# AE302F80F55D5AE_CM55_HP_View register map
Vendor: Alif Semiconductor; Series: E3; File version: 1.0
CPU: CM55 r1p0, selectable endian, MPU, FPU, double-precision FPU, DSP, VTOR, 8 interrupt priority bits, 1 SAU regions
Registers are 32-bit, read-write, reset 0x0 unless marked. A register's access mark holds for its fields unless they carry their own. Offsets are from the block's base; [hi:lo] are bit positions; lines under a group give offsets from that group; {n}, {i} and the like mark numbered series.

## STOP_MODE
Base 0x1A60F000
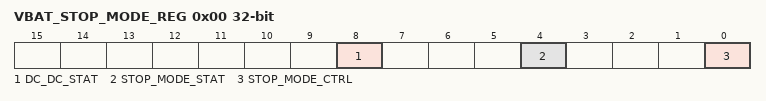
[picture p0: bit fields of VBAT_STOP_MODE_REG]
0x00 VBAT_STOP_MODE_REG — VBAT Stop Mode Control and Status Register
  [8] DC_DC_STAT ro — DC-DC Status Reflects the real-time status of DC-DC power
    0=DC-DC is ON; 1=DC-DC is OFF
  [4] STOP_MODE_STAT write-1-clears — Stop Mode Status - HW sets this bit when DC-DC was turned off - SW clears this bit by writing 0x1
  [0] STOP_MODE_CTRL — Stop Mode Control - SW sets this bit to enter stop mode - HW clears this bit when there is a wake-up event

## EVTRTR1
Base 0x400E2000
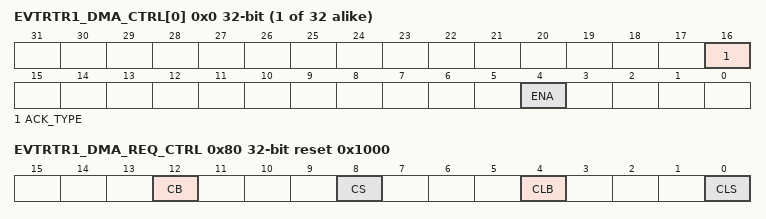
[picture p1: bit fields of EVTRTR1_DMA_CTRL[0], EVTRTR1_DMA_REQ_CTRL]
{0x0+4i} EVTRTR1_DMA_CTRL[{i}] (i=0..31) — DMA/Event Router Control and Status Register (n)
  [16] ACK_TYPE ro — DMA handshake type status for DMA peripheral
    0=Peripheral completes the REQ-ACK handshake with DMA controller. Event Router passing through REQ-ACK between DMA controller and peripheral.; 1=Event Router completes the REQ-ACK handshake with DMA controller. Peripheral raises DMA request without responding to ACK from DMA controller.
  [4] ENA — DMA channel enable
    0=Disable DMA channel; 1=Enable DMA channel
0x80 EVTRTR1_DMA_REQ_CTRL reset 0x1000 — DMA Request Control Register
  [all] fields
    0=Disable; 1=Enable
  [12] CB — Enable DMA request on DMACBREQ (DMAC Burst Request) Note: It is recommended to enable all DMA requests on the burst request line (DMACBREQ). For single transfer, the number of beats in a burst should be set to 1 (DMA_CCRn[SRC_BURST_LEN] = 0x0).
  [8] CS — Enable DMA request on DMACSREQ (DMAC Single Request) Note: It is recommended to enable all DMA requests on the burst request line (DMACBREQ), even for single transfer.
  [4] CLB — Enable DMA request on DMACLBREQ (DMAC Last Burst Request) Note: Do not use. The current implementation does not support transfers from a peripheral with an unspecified length ('peripheral length management').
  [0] CLS — Enable DMA request on DMACLSREQ (DMAC Last Single Request) Note: Do not use. The current implementation does not support transfers from a peripheral with an unspecified length ('peripheral length management').
0x90 EVTRTR1_DMA_ACK_TYPE0 reset 0xFF0000 — DMA Handshake Type Register 0
  [31:0] ACK — Select DMA handshake type for DMA group #0

## M55HP_CFG
Base 0x400F0000
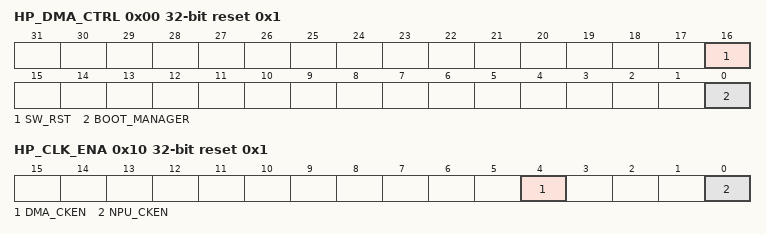
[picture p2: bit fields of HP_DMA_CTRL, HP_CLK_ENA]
0x00 HP_DMA_CTRL reset 0x1 — DMA1 Boot Control Register
  [16] SW_RST wo — Software reset for DMA1
    0=No reset; 1=Reset DMA1. This bit is self-cleared.
  [0] BOOT_MANAGER — When DMA1 exits from reset, this bit controls the security state of the DMA manager thread
    0=Assigns DMA manager to the secure state; 1=Assigns DMA manager to the non-secure state
0x04 HP_DMA_IRQ reset 0xFFFFFFFF — DMA1 Boot IRQ Non-Secure Register
  [31:0] BOOT_IRQ — Controls the security state of an event-interrupt resource, when DMA1 exits from reset
    0=DMA1 assigns event x or IRQ[x] to the secure state; 1=DMA1 assigns event x or IRQ[x] to the non-secure state
0x08 HP_DMA_PERIPH reset 0xFFFFFFFF — DMA1 Boot Peripheral Non-Secure Register
  [31:0] BOOT_PERIPH — Controls the security state of a peripheral request interface, when DMA1 exits from reset
    0=DMA1 assigns peripheral request interface x to the secure state; 1=DMA1 assigns peripheral request interface x to the non-secure state
0x0C HP_DMA_SEL — DMA1 Select Register
  [31:24] FLT_ENA — This field provides glitch filtering for the GPIO9_[7-0] signals that are mapped to DMA1 inputs [31-24] DMA1 (M55-HP) Requests Mapping). For each bit:
    0=Disable glitch-filter for GPIO input; 1=Enable glitch-filter for GPIO input
0x10 HP_CLK_ENA reset 0x1 — Peripheral Clock Enable Register
  [4] DMA_CKEN — Enable clock for DMA1 and EVTRTR1
    0=Disable clock; 1=Enable clock
  [0] NPU_CKEN — Enable clock for NPU-HP Note: When this bit is 0x1, the clock is automatically controlled. When this bit is 0x0, the clock is forcibly disabled, overriding the automatic control. Forcing this clock off can block RTSS-HP power domain state transitions or resets and does not save more power than the automatic gating. Therefore, this bit should remain 0x1 in normal operation. The control exists for test and debug purposes only.
    0=Disable clock; 1=Enable clock (automatic gating)
